# STM32F40x register map
File version: 1.5
Registers are 32-bit, read-write, reset 0x0 unless marked. A register's access mark holds for its fields unless they carry their own. Offsets are from the block's base; [hi:lo] are bit positions; {n}, {i} and the like mark numbered series; 'fields as' and 'values as' point back to an identical list.

## OTG_HS_GLOBAL（USB_OTG_HS_全局寄存器） — USB OTG HS 全局寄存器（best-effort） | USB on the go high speed
Base 0x40040000
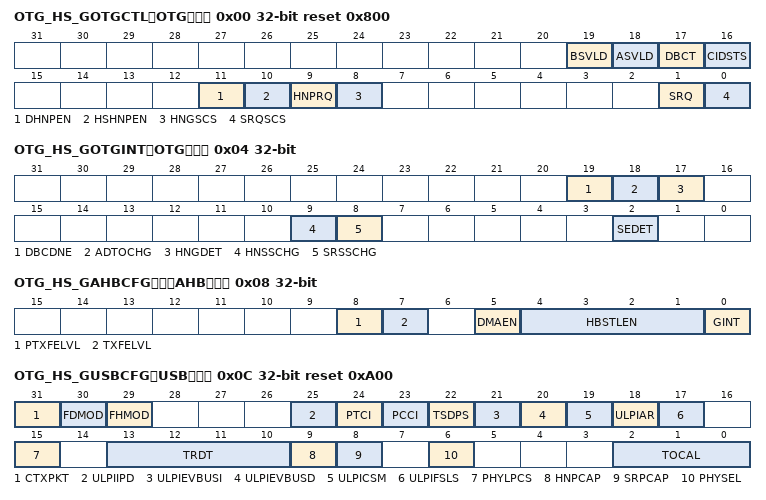
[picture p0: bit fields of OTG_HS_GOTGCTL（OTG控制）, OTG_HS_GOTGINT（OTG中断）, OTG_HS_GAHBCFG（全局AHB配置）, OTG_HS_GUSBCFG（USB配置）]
0x00 OTG_HS_GOTGCTL（OTG控制） access per field reset 0x800 — OTG 控制寄存器 | OTG_HS control and status register
  [19] BSVLD ro — B-session valid
  [18] ASVLD ro — A-session valid
  [17] DBCT ro — Long/short debounce time
  [16] CIDSTS ro — Connector ID status
  [11] DHNPEN rw — Device HNP enabled
  [10] HSHNPEN rw — Host set HNP enable
  [9] HNPRQ rw — HNP request
  [8] HNGSCS ro — Host negotiation success
  [1] SRQ rw — Session request
  [0] SRQSCS ro — Session request success
0x04 OTG_HS_GOTGINT（OTG中断） — OTG 中断寄存器 | OTG_HS interrupt register
  [19] DBCDNE — Debounce done
  [18] ADTOCHG — A-device timeout change
  [17] HNGDET — Host negotiation detected
  [9] HNSSCHG — Host negotiation success status change
  [8] SRSSCHG — Session request success status change
  [2] SEDET — Session end detected
0x08 OTG_HS_GAHBCFG（全局AHB配置） — 全局 AHB 配置 | OTG_HS AHB configuration register
  [8] PTXFELVL — Periodic TxFIFO empty level
  [7] TXFELVL — TxFIFO empty level
  [5] DMAEN — DMA enable
  [4:1] HBSTLEN — Burst length/type
  [0] GINT — Global interrupt mask
0x0C OTG_HS_GUSBCFG（USB配置） access per field reset 0xA00 — USB 配置 | OTG_HS USB configuration register
  [31] CTXPKT rw — Corrupt Tx packet
  [30] FDMOD rw — Forced peripheral mode
  [29] FHMOD rw — Forced host mode
  [25] ULPIIPD rw — ULPI interface protect disable
  [24] PTCI rw — Indicator pass through
  [23] PCCI rw — Indicator complement
  [22] TSDPS rw — TermSel DLine pulsing selection
  [21] ULPIEVBUSI rw — ULPI external VBUS indicator
  [20] ULPIEVBUSD rw — ULPI External VBUS Drive
  [19] ULPICSM rw — ULPI Clock SuspendM
  [18] ULPIAR rw — ULPI Auto-resume
  [17] ULPIFSLS rw — ULPI FS/LS select
  [15] PHYLPCS rw — PHY Low-power clock select
  [13:10] TRDT rw — USB turnaround time
  [9] HNPCAP rw — HNP-capable
  [8] SRPCAP rw — SRP-capable
  [6] PHYSEL wo — USB 2.0 high-speed ULPI PHY or USB 1.1 full-speed serial transceiver select
  [2:0] TOCAL rw — FS timeout calibration
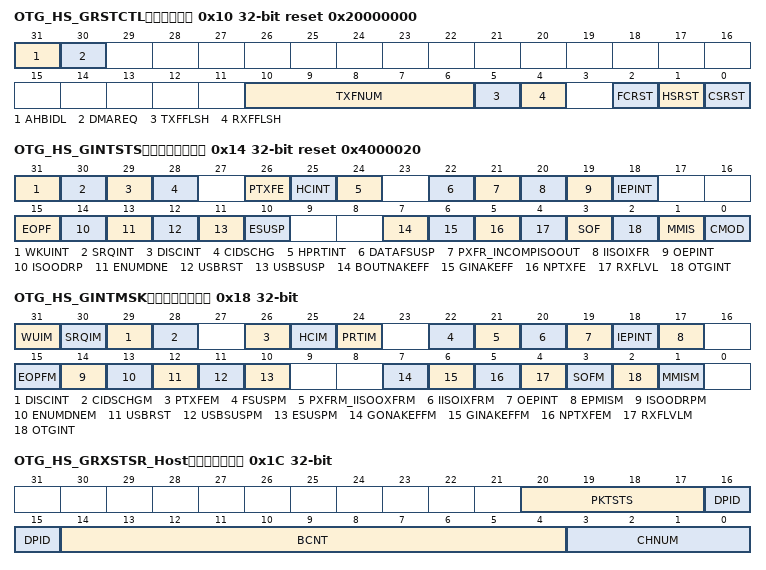
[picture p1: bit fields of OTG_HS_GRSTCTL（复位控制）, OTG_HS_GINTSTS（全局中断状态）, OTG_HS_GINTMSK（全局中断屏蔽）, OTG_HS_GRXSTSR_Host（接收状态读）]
0x10 OTG_HS_GRSTCTL（复位控制） access per field reset 0x20000000 — 复位控制 | OTG_HS reset register
  [31] AHBIDL ro — AHB master idle
  [30] DMAREQ ro — DMA request signal
  [10:6] TXFNUM rw — TxFIFO number
  [5] TXFFLSH rw — TxFIFO flush
  [4] RXFFLSH rw — RxFIFO flush
  [2] FCRST rw — Host frame counter reset
  [1] HSRST rw — HCLK soft reset
  [0] CSRST rw — Core soft reset
0x14 OTG_HS_GINTSTS（全局中断状态） access per field reset 0x4000020 — 全局中断状态 | OTG_HS core interrupt register
  [31] WKUINT rw — Resume/remote wakeup detected interrupt
  [30] SRQINT rw — Session request/new session detected interrupt
  [29] DISCINT rw — Disconnect detected interrupt
  [28] CIDSCHG rw — Connector ID status change
  [26] PTXFE ro — Periodic TxFIFO empty
  [25] HCINT ro — Host channels interrupt
  [24] HPRTINT ro — Host port interrupt
  [22] DATAFSUSP rw — Data fetch suspended
  [21] PXFR_INCOMPISOOUT rw — Incomplete periodic transfer
  [20] IISOIXFR rw — Incomplete isochronous IN transfer
  [19] OEPINT ro — OUT endpoint interrupt
  [18] IEPINT ro — IN endpoint interrupt
  [15] EOPF rw — End of periodic frame interrupt
  [14] ISOODRP rw — Isochronous OUT packet dropped interrupt
  [13] ENUMDNE rw — Enumeration done
  [12] USBRST rw — USB reset
  [11] USBSUSP rw — USB suspend
  [10] ESUSP rw — Early suspend
  [7] BOUTNAKEFF ro — Global OUT NAK effective
  [6] GINAKEFF ro — Global IN nonperiodic NAK effective
  [5] NPTXFE ro — Nonperiodic TxFIFO empty
  [4] RXFLVL ro — RxFIFO nonempty
  [3] SOF rw — Start of frame
  [2] OTGINT ro — OTG interrupt
  [1] MMIS rw — Mode mismatch interrupt
  [0] CMOD ro — Current mode of operation
0x18 OTG_HS_GINTMSK（全局中断屏蔽） access per field — 全局中断屏蔽 | OTG_HS interrupt mask register
  [31] WUIM rw — Resume/remote wakeup detected interrupt mask
  [30] SRQIM rw — Session request/new session detected interrupt mask
  [29] DISCINT rw — Disconnect detected interrupt mask
  [28] CIDSCHGM rw — Connector ID status change mask
  [26] PTXFEM rw — Periodic TxFIFO empty mask
  [25] HCIM rw — Host channels interrupt mask
  [24] PRTIM ro — Host port interrupt mask
  [22] FSUSPM rw — Data fetch suspended mask
  [21] PXFRM_IISOOXFRM rw — Incomplete periodic transfer mask
  [20] IISOIXFRM rw — Incomplete isochronous IN transfer mask
  [19] OEPINT rw — OUT endpoints interrupt mask
  [18] IEPINT rw — IN endpoints interrupt mask
  [17] EPMISM rw — Endpoint mismatch interrupt mask
  [15] EOPFM rw — End of periodic frame interrupt mask
  [14] ISOODRPM rw — Isochronous OUT packet dropped interrupt mask
  [13] ENUMDNEM rw — Enumeration done mask
  [12] USBRST rw — USB reset mask
  [11] USBSUSPM rw — USB suspend mask
  [10] ESUSPM rw — Early suspend mask
  [7] GONAKEFFM rw — Global OUT NAK effective mask
  [6] GINAKEFFM rw — Global nonperiodic IN NAK effective mask
  [5] NPTXFEM rw — Nonperiodic TxFIFO empty mask
  [4] RXFLVLM rw — Receive FIFO nonempty mask
  [3] SOFM rw — Start of frame mask
  [2] OTGINT rw — OTG interrupt mask
  [1] MMISM rw — Mode mismatch interrupt mask
0x1C OTG_HS_GRXSTSR_Host（接收状态读） ro — 接收状态（读） | OTG_HS Receive status debug read register (host mode)
  [20:17] PKTSTS — Packet status
  [16:15] DPID — Data PID
  [14:4] BCNT — Byte count
  [3:0] CHNUM — Channel number
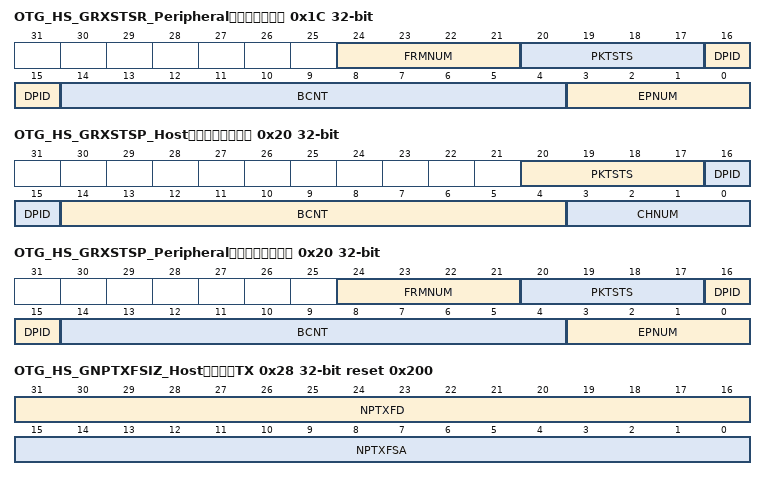
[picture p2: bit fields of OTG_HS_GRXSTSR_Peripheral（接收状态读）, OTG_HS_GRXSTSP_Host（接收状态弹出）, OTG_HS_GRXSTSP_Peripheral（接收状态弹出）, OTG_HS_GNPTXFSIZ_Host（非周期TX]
0x1C OTG_HS_GRXSTSR_Peripheral（接收状态读） ro (alternate view of OTG_HS_GRXSTSR_Host) — 接收状态（读） | OTG_HS Receive status debug read register (peripheral mode mode)
  [24:21] FRMNUM — Frame number
  [20:17] PKTSTS — Packet status
  [16:15] DPID — Data PID
  [14:4] BCNT — Byte count
  [3:0] EPNUM — Endpoint number
0x20 OTG_HS_GRXSTSP_Host（接收状态弹出） ro — 接收状态（弹出） | OTG_HS status read and pop register (host mode)
  fields as OTG_HS_GRXSTSR_Host（接收状态读）
0x20 OTG_HS_GRXSTSP_Peripheral（接收状态弹出） ro (alternate view of OTG_HS_GRXSTSP_Host) — 接收状态（弹出） | OTG_HS status read and pop register (peripheral mode)
  fields as OTG_HS_GRXSTSR_Peripheral（接收状态读）
0x24 OTG_HS_GRXFSIZ（接收FIFO大小） reset 0x200 — 接收 FIFO 大小 | OTG_HS Receive FIFO size register
  [15:0] RXFD — RxFIFO depth
0x28 OTG_HS_GNPTXFSIZ_Host（非周期TX FIFO大小） reset 0x200 — 非周期发送 FIFO 大小 | OTG_HS nonperiodic transmit FIFO size register (host mode)
  [31:16] NPTXFD — Nonperiodic TxFIFO depth
  [15:0] NPTXFSA — Nonperiodic transmit RAM start address
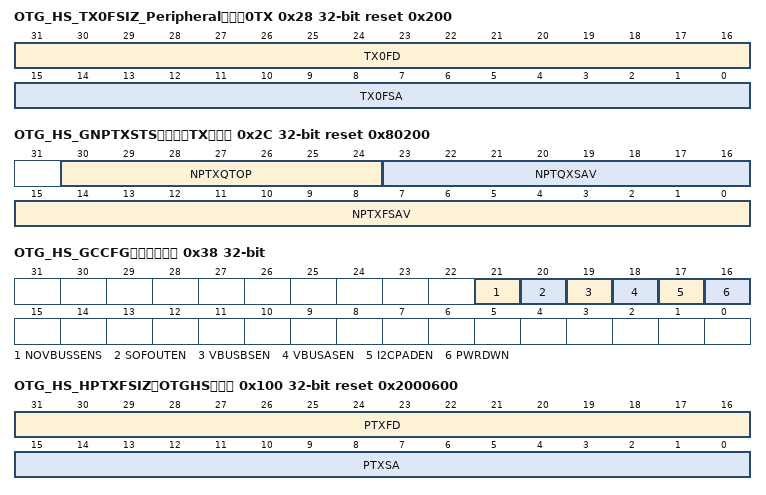
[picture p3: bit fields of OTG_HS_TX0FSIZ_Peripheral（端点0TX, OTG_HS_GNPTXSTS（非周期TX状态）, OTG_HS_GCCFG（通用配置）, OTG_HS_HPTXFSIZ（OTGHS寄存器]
0x28 OTG_HS_TX0FSIZ_Peripheral（端点0TX FIFO） reset 0x200 (alternate view of OTG_HS_GNPTXFSIZ_Host) — 端点0 发送 FIFO 大小 | Endpoint 0 transmit FIFO size (peripheral mode)
  [31:16] TX0FD — Endpoint 0 TxFIFO depth
  [15:0] TX0FSA — Endpoint 0 transmit RAM start address
0x2C OTG_HS_GNPTXSTS（非周期TX状态） ro reset 0x80200 — 非周期发送状态 | OTG_HS nonperiodic transmit FIFO/queue status register
  [30:24] NPTXQTOP — Top of the nonperiodic transmit request queue
  [23:16] NPTQXSAV — Nonperiodic transmit request queue space available
  [15:0] NPTXFSAV — Nonperiodic TxFIFO space available
0x38 OTG_HS_GCCFG（通用配置） — 通用配置 | OTG_HS general core configuration register
  [21] NOVBUSSENS — VBUS sensing disable option
  [20] SOFOUTEN — SOF output enable
  [19] VBUSBSEN — Enable the VBUS sensing device
  [18] VBUSASEN — Enable the VBUS sensing device
  [17] I2CPADEN — Enable I2C bus connection for the external I2C PHY interface
  [16] PWRDWN — Power down
0x3C OTG_HS_CID（芯片ID） reset 0x1200 — 芯片 ID | OTG_HS core ID register
  [31:0] PRODUCT_ID
0x100 OTG_HS_HPTXFSIZ（OTGHS寄存器 HPTXFSIZ） reset 0x2000600 — USB OTG HS 寄存器 HPTXFSIZ（best-effort） | OTG_HS Host periodic transmit FIFO size register
  [31:16] PTXFD — Host periodic TxFIFO depth
  [15:0] PTXSA — Host periodic TxFIFO start address
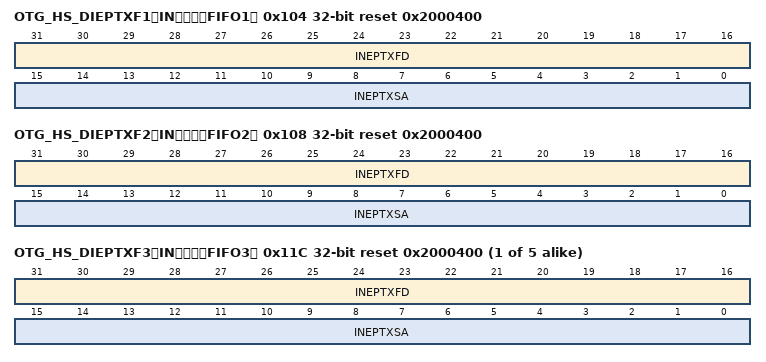
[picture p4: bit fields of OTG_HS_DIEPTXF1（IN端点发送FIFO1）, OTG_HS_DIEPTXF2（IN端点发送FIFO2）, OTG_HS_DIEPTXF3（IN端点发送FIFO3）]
0x104 OTG_HS_DIEPTXF1（IN端点发送FIFO1） reset 0x2000400 — USB OTG HS IN端点发送FIFO1 | OTG_HS device IN endpoint transmit FIFO size register
  [31:16] INEPTXFD — IN endpoint TxFIFO depth
  [15:0] INEPTXSA — IN endpoint FIFOx transmit RAM start address
0x108 OTG_HS_DIEPTXF2（IN端点发送FIFO2） reset 0x2000400 — USB OTG HS IN端点发送FIFO2 | OTG_HS device IN endpoint transmit FIFO size register
  fields as OTG_HS_DIEPTXF1（IN端点发送FIFO1）
{0x110+4i} OTG_HS_DIEPTXF{i}（IN端点发送FIFO{i}） reset 0x2000400 (i=3..7) — USB OTG HS IN端点发送FIFO{i} | OTG_HS device IN endpoint transmit FIFO size register
  fields as OTG_HS_DIEPTXF1（IN端点发送FIFO1）
